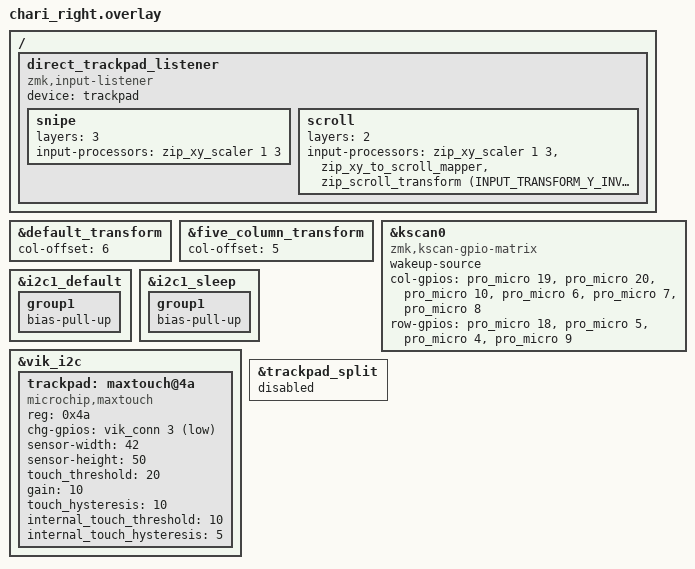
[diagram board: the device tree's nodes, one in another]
#include "chari.dtsi"
#include <dt-bindings/zmk/input_transform.h>
#include <input/processors.dtsi>

&default_transform {
	col-offset = <6>;
};

&five_column_transform {
	col-offset = <5>;
};

&kscan0 {
	compatible = "zmk,kscan-gpio-matrix";
	wakeup-source;

	col-gpios
		= <&pro_micro 19 (GPIO_ACTIVE_HIGH | GPIO_PULL_DOWN)>
		, <&pro_micro 20 (GPIO_ACTIVE_HIGH | GPIO_PULL_DOWN)>
		, <&pro_micro 10 (GPIO_ACTIVE_HIGH | GPIO_PULL_DOWN)>
		, <&pro_micro 6 (GPIO_ACTIVE_HIGH | GPIO_PULL_DOWN)>
		, <&pro_micro 7 (GPIO_ACTIVE_HIGH | GPIO_PULL_DOWN)>
		, <&pro_micro 8 (GPIO_ACTIVE_HIGH | GPIO_PULL_DOWN)>
		;

	row-gpios
		= <&pro_micro 18 GPIO_ACTIVE_HIGH>
		, <&pro_micro 5 GPIO_ACTIVE_HIGH>
		, <&pro_micro 4 GPIO_ACTIVE_HIGH>
		, <&pro_micro 9 GPIO_ACTIVE_HIGH>
		;
};

/* Procyon trackpad via VIK I2C */
&i2c1_default {
	group1 {
		bias-pull-up;
	};
};

&i2c1_sleep {
	group1 {
		bias-pull-up;
	};
};

&vik_i2c {
	status = "okay";

	trackpad: maxtouch@4a {
		compatible = "microchip,maxtouch";
		reg = <0x4a>;
		chg-gpios = <&vik_conn 3 (GPIO_ACTIVE_LOW | GPIO_PULL_UP)>;
		sensor-width = <42>;
		sensor-height = <50>;
		touch_threshold = <20>;
		gain = <10>;
		touch_hysteresis = <10>;
		internal_touch_threshold = <10>;
		internal_touch_hysteresis = <5>;
	};
};

/* Non-dongle: right is central, listen directly */
/ {
	direct_trackpad_listener {
		compatible = "zmk,input-listener";
		device = <&trackpad>;

		snipe {
			layers = <3>;
			input-processors = <&zip_xy_scaler 1 3>;
		};

		scroll {
			layers = <2>;
			input-processors = <&zip_xy_scaler 1 3>, <&zip_xy_to_scroll_mapper>, <&zip_scroll_transform (INPUT_TRANSFORM_Y_INVERT)>;
		};
	};
};

/* Disable the split listener (not needed when right is central) */
&trackpad_split {
	status = "disabled";
};
